# TOP_MDO_INFRA register map
Vendor: Texas Instruments
Peripheral module from a debugger description file (folder awr2x44p).
Registers are 32-bit, read-write, no defined reset value unless marked. A register's access mark holds for its fields unless they carry their own. Offsets are as the file gives them; lines under a group give offsets from that group; [hi:lo] are bit positions; {n}, {i} and the like mark numbered series; 'fields as' and 'values as' point back to an identical list; <NAME> marks a mode.

## TOP_MDO_INFRA
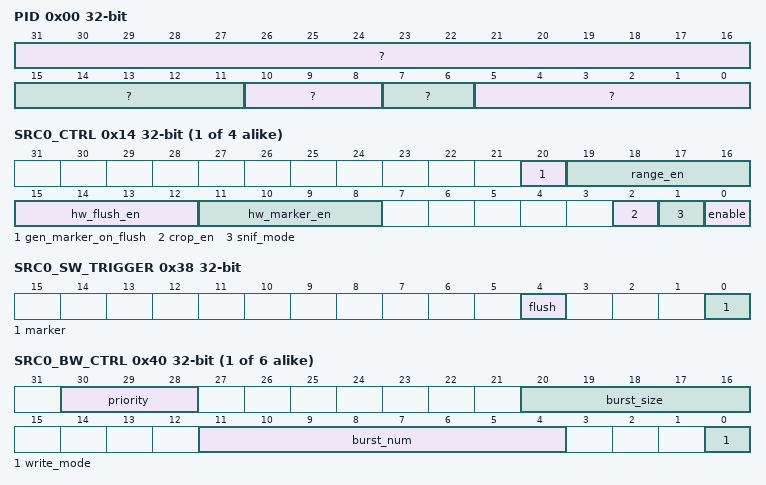
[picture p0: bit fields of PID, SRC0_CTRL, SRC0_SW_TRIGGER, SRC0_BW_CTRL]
0x00 PID ro
  [31:16] ?, [15:11] ?, [10:8] ?, [7:6] ?, [5:0] ?
0x04 HW_REG0
  [31:0] hwreg — HW Reserved regiser
0x08 HW_REG1
  [31:0] hwreg — HW Reserved regiser
0x0C PREVIOUS_NAME
  [31:0] hwreg — HW Reserved regiser
0x10 HW_REG3
  [31:0] hwreg — HW Reserved regiser
{0x14+0x38*i} SRC{i}_CTRL (i=0..3)
  [20] gen_marker_on_flush — Write 0x1 to generate a marker on Flush trigger
  [19:16] range_en — Enable the corresponding range for data capture. Bit 0 : 0: Range 0 is disabled 1 : Range 0 is enableld
  [15:12] hw_flush_en — Write 0x1 to enable HW Marker trigger to generate a Flush
  [11:8] hw_marker_en — Write 0x1 to enable HW Marker trigger to generate a Marker
  [2] crop_en — Chop of the sign extension bits [15:12] for every 16 bits of data. 0 : Send all 16 bits 1 : Send lower 12 of 16 bits
  [1] snif_mode — Select which bus to capture. 0 : Write Bus 1 : Read Bus
  [0] enable — Indicates is the sniffer block is active or inactive. 0 : Captuere is Disabled 1 : Sniffer Enabled
{0x18+0x38*i} SRC{i}_RANGE_START0 (i=0..5)
  [31:0] start — Range 0 Start address OR Start param number for HWA , which needs to be captured
{0x1C+0x38*i} SRC{i}_RANGE_END0 (i=0..5)
  [31:0] end — Range 0 End address OR End param number for HWA , which needs to be captured
{0x20+0x38*i} SRC{i}_RANGE_START1 (i=0..5)
  [31:0] start — Range 1 Start address OR Start param number for HWA , which needs to be captured
{0x24+0x38*i} SRC{i}_RANGE_END1 (i=0..5)
  [31:0] end — Range 1 End address OR End param number for HWA , which needs to be captured
{0x28+0x38*i} SRC{i}_RANGE_START2 (i=0..5)
  [31:0] start — Range 2 Start address OR Start param number for HWA , which needs to be captured
{0x2C+0x38*i} SRC{i}_RANGE_END2 (i=0..5)
  [31:0] end — Range 2 End address OR End param number for HWA , which needs to be captured
{0x30+0x38*i} SRC{i}_RANGE_START3 (i=0..5)
  [31:0] start — Range 3 Start address OR Start param number for HWA , which needs to be captured
{0x34+0x38*i} SRC{i}_RANGE_END3 (i=0..5)
  [31:0] end — Range 3 End address OR End param number for HWA , which needs to be captured
0x38 SRC0_SW_TRIGGER
  [4] flush — write pulse bit field:Write 0x1 to trigger a Flush. A marker packet will also be inserted
  [0] marker — write pulse bit field:Write 0x1 to insert a Marker
{0x3C+0x38*i} SRC{i}_THRESHOLD (i=0..5)
  [9:0] threshold — The FIFO threshold to trigger writes from the Source FIFO. This value is in multiples of 32 bytes. If SRCx_BW_CTRL_WRITE_MODE is 0x0, then the bits [9:5] of this field need to be programmed to 0x0
{0x40+0x38*i} SRC{i}_BW_CTRL (i=0..5)
  [30:28] priority — 0 : Highest Dynamic Priority 7 : Lowest Dynamic Priority
  [20:16] burst_size — The burst_size is the minimum size for which the SRC will keep arbitration once it wins . The value in multiples of 32 bytes
  [11:4] burst_num — The FIFO threshold to trigger writes from the Source FIFO. Value to be aligned to 32 bytes [4:0] should be 0x0
  [0] write_mode — 0 : Send data equivalent to threshold size. This can be set only if threshold is less than 1024 bytes 1 : Send data equivalent to burst_count * burst_size
{0x44+0x38*i} SRC{i}_CHANNEL (i=0..5)
  [31:0] addr — Configure the STM channel number on bits [31:8] . If channel number is 3 , configure bits [31:8] =3
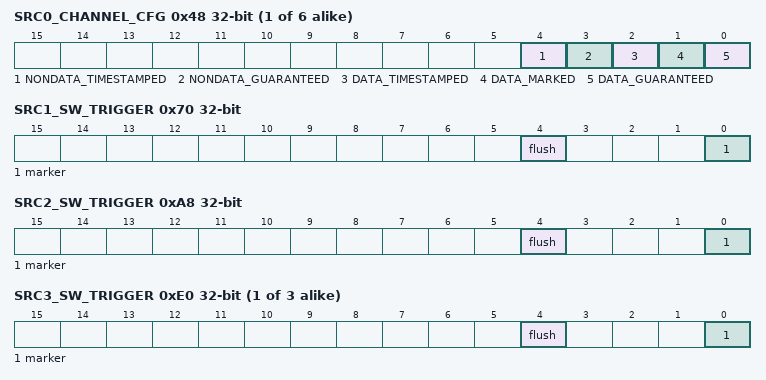
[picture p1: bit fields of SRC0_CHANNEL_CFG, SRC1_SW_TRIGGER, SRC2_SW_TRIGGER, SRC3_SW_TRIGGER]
{0x48+0x38*i} SRC{i}_CHANNEL_CFG (i=0..5)
  [4] NONDATA_TIMESTAMPED — Selects whether the Non Data access for the Source is timestamped 0 : No Timestamp 1 : Timestamped
  [3] NONDATA_GUARANTEED — Selects whether the Non Data access for the Source is Guaranteed or Invariant Timing 0 : Time Invariant 1 : Guaranteed
  [2] DATA_TIMESTAMPED — Selects whether the Data access for the Source is timestamped 0 : No Timestamp 1 : Timestamped
  [1] DATA_MARKED — Selects whether the Data access for the Source is marked 0 : Un-Marked 1 : Marked
  [0] DATA_GUARANTEED — Selects whether the Data access for the Source is Guaranteed or Invariant Timing 0 : Time Invariant 1 : Guaranteed
0x70 SRC1_SW_TRIGGER
  fields as SRC0_SW_TRIGGER
0xA8 SRC2_SW_TRIGGER
  [4] flush — write pulse bit field:Write 0x1 to trigger a Flush.
  [0] marker — write pulse bit field:Write 0x1 to insert a Marker
{0x38+0x38*i} SRC{i}_SW_TRIGGER (i=3..5)
  fields as SRC0_SW_TRIGGER
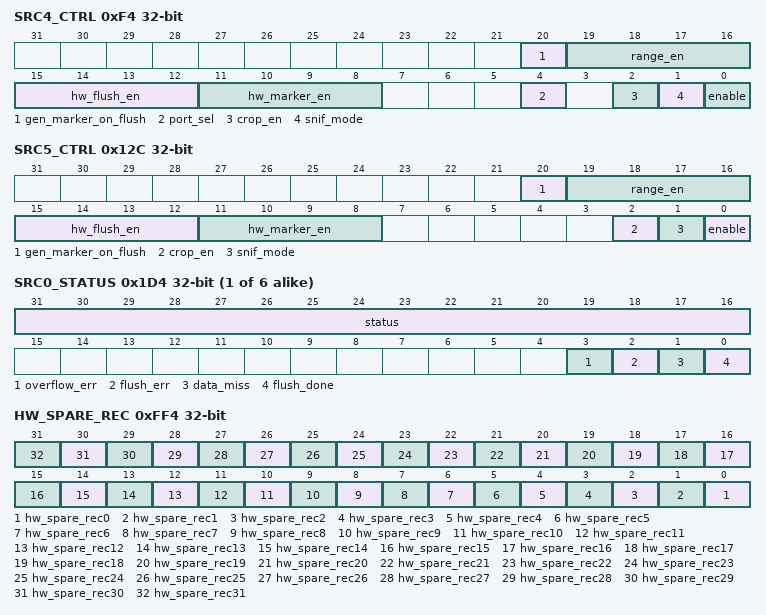
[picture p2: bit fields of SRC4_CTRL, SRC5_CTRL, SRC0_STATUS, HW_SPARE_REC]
0xF4 SRC4_CTRL
  [20] gen_marker_on_flush — Write 0x1 to generate a marker on Flush trigger
  [19:16] range_en — Enable the corresponding range for data capture. Bit 0 : 0: Range 0 is disabled 1 : Range 0 is enableld
  [15:12] hw_flush_en — Write 0x1 to enable HW Marker trigger to generate a Flush
  [11:8] hw_marker_en — Write 0x1 to enable HW Marker trigger to generate a Marker
  [4] port_sel — Select which bus to capture. 0 : DSS_HWA_DMA0 1 : DSS_HWA_DMA1
  [2] crop_en — Chop of the sign extension bits [15:12] for every 16 bits of data. 0 : Send all 16 bits 1 : Send lower 12 of 16 bits
  [1] snif_mode — Select which bus to capture. 0 : Write Bus 1 : Read Bus
  [0] enable — Indicates is the sniffer block is active or inactive. 0 : Captuere is Disabled 1 : Sniffer Enabled
0x12C SRC5_CTRL
  fields as SRC0_CTRL
{0x1D4+4i} SRC{i}_STATUS access per field (i=0..5)
  [31:16] status ro — Status of the Sniffer for Source {i}
  [3] overflow_err rw — Rising Edge Capture reg (write 1 to clear): Source Overflow Error is generated with the Source FIFO is full and there is no space to write the sniffed data
  [2] flush_err rw — Rising Edge Capture reg (write 1 to clear): Flush Err is generated on Multiple Flush requests
  [1] data_miss rw — Rising Edge Capture reg (write 1 to clear): Data Miss Erro is generated when a Flush or Marker Requested causes Miss in the Sniffer data
  [0] flush_done rw — Rising Edge Capture reg (write 1 to clear): Flush Done is generated on completion of a flush request
0x1EC INTERRUPT_MASK
  [31:0] mask — MDO Infra Interrupt Mask
{0xFD0+4i} HW_SPARE_RW{i} (i=0..3)
  [31:0] hw_spare_rw{i} — Reserved for HW R&D
{0xFE0+4i} HW_SPARE_RO{i} ro (i=0..3)
  [31:0] hw_spare_ro{i} — Reserved for HW R&D
0xFF0 HW_SPARE_WPH
  [31:0] hw_spare_wph — write pulse bit field:Reserved for HW R&D
0xFF4 HW_SPARE_REC
  [n] hw_spare_rec{n} (n=0..31) — Rising Edge Capture reg (write 1 to clear): Reserved for HW R&D
0x1008 LOCK0_KICK0 — - KICK0 component
  [31:0] ?
0x100C LOCK0_KICK1 — - KICK1 component
  [31:0] ?
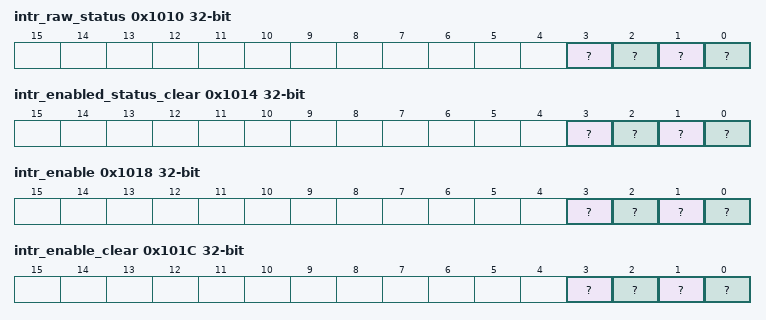
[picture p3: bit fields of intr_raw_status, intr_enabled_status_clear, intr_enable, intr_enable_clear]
0x1010 intr_raw_status — Interrupt Raw Status/Set Register
  [3] ? — Proxy0 access violation error. Raw status is read. Write a 1 to set the status. Writing a 0 has no effect.
  [2] ? — Kick access violation error. Raw status is read. Write a 1 to set the status. Writing a 0 has no effect.
  [1] ? — Addressing violation error. Raw status is read. Write a 1 to set the status. Writing a 0 has no effect.
  [0] ? — Protection violation error. Raw status is read. Write a 1 to set the status. Writing a 0 has no effect.
0x1014 intr_enabled_status_clear — Interrupt Enabled Status/Clear register
  [3] ? — Proxy0 access violation error. Enabled status is read. Write a 1 to clear the status. Writing a 0 has no effect.
  [2] ? — Kick access violation error. Enabled status is read. Write a 1 to clear the status. Writing a 0 has no effect.
  [1] ? — Addressing violation error. Enabled status is read. Write a 1 to clear the status. Writing a 0 has no effect.
  [0] ? — Protection violation error. Enabled status is read. Write a 1 to clear the status. Writing a 0 has no effect.
0x1018 intr_enable — Interrupt Enable register
  [3] ? — Proxy0 access violation error enable. Write a 1 to set the enable. Writing a 0 has no effect.
  [2] ? — Kick access violation error enable. Write a 1 to set the enable. Writing a 0 has no effect.
  [1] ? — Addressing violation error enable. Write a 1 to set the enable. Writing a 0 has no effect.
  [0] ? — Protection violation error enable. Write a 1 to set the enable. Writing a 0 has no effect.
0x101C intr_enable_clear — Interrupt Enable Clear register
  [3] ? — Proxy0 access violation error enable clear. Write a 1 to clear the enable. Writing a 0 has no effect.
  [2] ? — Kick access violation error enable clear. Write a 1 to clear the enable. Writing a 0 has no effect.
  [1] ? — Addressing violation error enable clear. Write a 1 to clear the enable. Writing a 0 has no effect.
  [0] ? — Protection violation error enable clear. Write a 1 to clear the enable. Writing a 0 has no effect.
0x1020 eoi
  [7:0] ? — EOI vector value. Write this with interrupt distribution value in the chip.
0x1024 fault_address ro
  [31:0] ? — Fault Address.
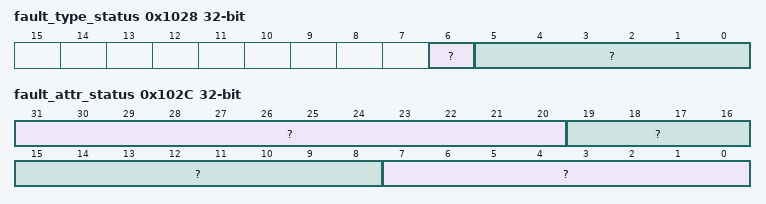
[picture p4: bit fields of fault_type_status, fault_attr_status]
0x1028 fault_type_status ro
  [6] ? — Non-secure access.
  [5:0] ? — Fault Type 10_0000 = Supervisor read fault - priv = 1 dir = 1 dtype != 1 01_0000 = Supervisor write fault - priv = 1 dir = 0 00_1000 = Supervisor execute fault - priv = 1 dir = 1 dtype = 1 00_0100 = User read fault - priv = 0 dir = 1 dtype = 1 00_0010 = User write fault - priv = 0 dir = 0 00_0001 = User execute fault - priv = 0 dir = 1 dtype = 1 00_0000 = No fault
0x102C fault_attr_status ro — Fault Attribute Status register
  [31:20] ? — XID.
  [19:8] ? — Route ID.
  [7:0] ? — Privilege ID.
0x1030 fault_clear wo
  [0] ? — Fault clear. Writing a 1 clears the current fault. Writing a 0 has no effect.
